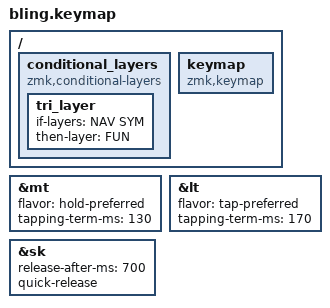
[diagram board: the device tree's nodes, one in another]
#include <behaviors.dtsi>
#include <dt-bindings/zmk/keys.h>
#include <dt-bindings/zmk/bt.h>
#include <dt-bindings/zmk/outputs.h>

#define BASE 0
#define NAV  1
#define SYM  2
#define FUN  3
#define SYS  4

&mt {
  flavor = "hold-preferred";
  tapping-term-ms = <130>;
};

&lt {
  flavor = "tap-preferred";
  tapping-term-ms = <170>;
};

&sk {
  release-after-ms = <700>;
  quick-release;
};

/ {

  // #include "combos.dtsi"

  conditional_layers {
    compatible = "zmk,conditional-layers";
      tri_layer {
          if-layers = <NAV SYM>;
          then-layer = <FUN>;
      };
  };

  keymap {
    compatible = "zmk,keymap";
    #include "34-keys.dtsi"
  };

};
